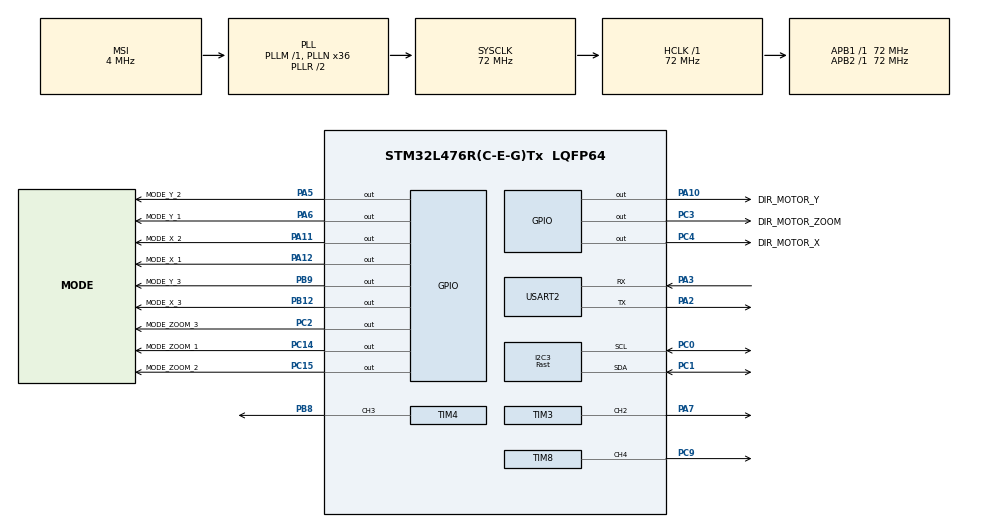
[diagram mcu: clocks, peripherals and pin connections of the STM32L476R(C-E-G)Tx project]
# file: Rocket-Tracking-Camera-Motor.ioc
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FREERTOS.Tasks01=defaultTask,24,128,StartDefaultTask,Default,NULL,Dynamic,NULL,NULL;motor_control,32,128,tsk_motor_control,As external,NULL,Dynamic,NULL,NULL;i2c,32,128,tsk_i2c,As external,NULL,Dynamic,NULL,NULL
FREERTOS.configUSE_NEWLIB_REENTRANT=1
I2C3.I2C_Speed_Mode=I2C_Fast
I2C3.OwnAddress=0x23
I2C3.Timing=0x00702681
Mcu.Family=STM32L4
Mcu.Name=STM32L476R(C-E-G)Tx
Mcu.Package=LQFP64
NVIC.I2C3_ER_IRQn=true\:5\:0\:false\:false\:true\:true\:true\:true\:true
NVIC.I2C3_EV_IRQn=true\:5\:0\:false\:false\:true\:true\:true\:true\:true
NVIC.PriorityGroup=NVIC_PRIORITYGROUP_4
NVIC.TIM1_UP_TIM16_IRQn=true\:15\:0\:false\:false\:true\:false\:false\:true\:true
NVIC.TimeBase=TIM1_UP_TIM16_IRQn
NVIC.TimeBaseIP=TIM1
PA10.GPIO_Label=DIR_MOTOR_Y
PA10.Signal=GPIO_Output
PA11.GPIO_Label=MODE_X_2
PA11.Signal=GPIO_Output
PA12.GPIO_Label=MODE_X_1
PA12.Signal=GPIO_Output
PA13\ (JTMS-SWDIO).Mode=Trace_Asynchronous_SW
PA13\ (JTMS-SWDIO).Signal=SYS_JTMS-SWDIO
PA14\ (JTCK-SWCLK).Mode=Trace_Asynchronous_SW
PA14\ (JTCK-SWCLK).Signal=SYS_JTCK-SWCLK
PA2.Mode=Asynchronous
PA2.Signal=USART2_TX
PA3.Mode=Asynchronous
PA3.Signal=USART2_RX
PA5.GPIO_Label=MODE_Y_2
PA5.Signal=GPIO_Output
PA6.GPIO_Label=MODE_Y_1
PA6.Signal=GPIO_Output
PA7.Signal=S_TIM3_CH2
PB12.GPIO_Label=MODE_X_3
PB12.Signal=GPIO_Output
PB13.Signal=I2C2_SCL
PB14.Signal=I2C2_SDA
PB3\ (JTDO-TRACESWO).Mode=Trace_Asynchronous_SW
PB3\ (JTDO-TRACESWO).Signal=SYS_JTDO-SWO
PB8.Signal=S_TIM4_CH3
PB9.GPIO_Label=MODE_Y_3
PB9.Signal=GPIO_Output
PC0.Mode=I2C
PC0.Signal=I2C3_SCL
PC1.Mode=I2C
PC1.Signal=I2C3_SDA
PC14-OSC32_IN\ (PC14).GPIO_Label=MODE_ZOOM_1
PC14-OSC32_IN\ (PC14).Signal=GPIO_Output
PC15-OSC32_OUT\ (PC15).GPIO_Label=MODE_ZOOM_2
PC15-OSC32_OUT\ (PC15).Signal=GPIO_Output
PC2.GPIO_Label=MODE_ZOOM_3
PC2.Signal=GPIO_Output
PC3.GPIO_Label=DIR_MOTOR_ZOOM
PC3.Signal=GPIO_Output
PC4.GPIO_Label=DIR_MOTOR_X
PC4.Signal=GPIO_Output
PC9.Signal=S_TIM8_CH4
PH0-OSC_IN\ (PH0).Mode=HSE-External-Oscillator
PH0-OSC_IN\ (PH0).Signal=RCC_OSC_IN
PH1-OSC_OUT\ (PH1).Mode=HSE-External-Oscillator
PH1-OSC_OUT\ (PH1).Signal=RCC_OSC_OUT
ProjectManager.HeapSize=0x200
ProjectManager.StackSize=0x400
ProjectManager.TargetToolchain=STM32CubeIDE
RCC.AHBFreq_Value=72000000
RCC.APB1Freq_Value=72000000
RCC.APB1TimFreq_Value=72000000
RCC.APB2Freq_Value=72000000
RCC.APB2TimFreq_Value=72000000
RCC.CortexFreq_Value=72000000
RCC.HCLKFreq_Value=72000000
RCC.HSE_VALUE=8000000
RCC.HSI_VALUE=16000000
RCC.LSE_VALUE=32768
RCC.MSI_VALUE=4000000
RCC.PLLN=36
RCC.SYSCLKFreq_VALUE=72000000
RCC.SYSCLKSource=RCC_SYSCLKSOURCE_PLLCLK
RCC.VCOOutputFreq_Value=144000000
SH.S_TIM3_CH2.0=TIM3_CH2,PWM Generation2 CH2
SH.S_TIM4_CH3.0=TIM4_CH3,PWM Generation3 CH3
SH.S_TIM8_CH4.0=TIM8_CH4,PWM Generation4 CH4
TIM3.AutoReloadPreload=TIM_AUTORELOAD_PRELOAD_ENABLE
TIM3.Channel-PWM\ Generation2\ CH2=TIM_CHANNEL_2
TIM4.AutoReloadPreload=TIM_AUTORELOAD_PRELOAD_ENABLE
TIM4.Channel-PWM\ Generation3\ CH3=TIM_CHANNEL_3
TIM8.AutoReloadPreload=TIM_AUTORELOAD_PRELOAD_ENABLE
TIM8.Channel-PWM\ Generation4\ CH4=TIM_CHANNEL_4
USART2.VirtualMode-Asynchronous=VM_ASYNC
VP_FREERTOS_VS_CMSIS_V2.Mode=CMSIS_V2
VP_SYS_VS_tim1.Mode=TIM1
VP_TIM3_VS_ClockSourceINT.Mode=Internal
VP_TIM4_VS_ClockSourceINT.Mode=Internal
VP_TIM8_VS_ClockSourceINT.Mode=Internal
board=custom

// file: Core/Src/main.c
/* USER CODE BEGIN Header */
/**
  ******************************************************************************
  * @file           : main.c
  * @brief          : Main program body
  ******************************************************************************
  * @attention
  *
  * Copyright (c) 2023 STMicroelectronics.
  * All rights reserved.
  *
  * This software is licensed under terms that can be found in the LICENSE file
  * in the root directory of this software component.
  * If no LICENSE file comes with this software, it is provided AS-IS.
  *
  ******************************************************************************
  */
/* USER CODE END Header */
#include "main.h"
#include "cmsis_os.h"

/* USER CODE BEGIN Includes */
#include <string.h>

/* USER CODE END Includes */

I2C_HandleTypeDef hi2c3;

TIM_HandleTypeDef htim3;
TIM_HandleTypeDef htim4;
TIM_HandleTypeDef htim8;

UART_HandleTypeDef huart2;

/* Definitions for defaultTask */
osThreadId_t defaultTaskHandle;
const osThreadAttr_t defaultTask_attributes = {
  .name = "defaultTask",
  .stack_size = 128 * 4,
  .priority = (osPriority_t) osPriorityNormal,
};
/* Definitions for motor_control */
osThreadId_t motor_controlHandle;
const osThreadAttr_t motor_control_attributes = {
  .name = "motor_control",
  .stack_size = 128 * 4,
  .priority = (osPriority_t) osPriorityAboveNormal,
};
/* Definitions for i2c */
osThreadId_t i2cHandle;
const osThreadAttr_t i2c_attributes = {
  .name = "i2c",
  .stack_size = 128 * 4,
  .priority = (osPriority_t) osPriorityAboveNormal,
};

void SystemClock_Config(void);
static void MX_GPIO_Init(void);
static void MX_TIM3_Init(void);
static void MX_TIM8_Init(void);
static void MX_TIM4_Init(void);
static void MX_USART2_UART_Init(void);
static void MX_I2C3_Init(void);
void StartDefaultTask(void *argument);
extern void tsk_motor_control(void *argument);
extern void tsk_i2c(void *argument);

/* USER CODE BEGIN 0 */

TIM_HandleTypeDef* get_htim3()  { return &htim3;}
TIM_HandleTypeDef* get_htim4()  { return &htim4;}
TIM_HandleTypeDef* get_htim8()  { return &htim8;}
I2C_HandleTypeDef* get_hi2cl()  { return &hi2c3; }
UART_HandleTypeDef* get_huart2(){ return &huart2; }

/* USER CODE END 0 */

int main(void)
{

  /* MCU Configuration--------------------------------------------------------*/

  /* Reset of all peripherals, Initializes the Flash interface and the Systick. */
  HAL_Init();

  /* Configure the system clock */
  SystemClock_Config();

  /* Initialize all configured peripherals */
  MX_GPIO_Init();
  MX_TIM3_Init();
  MX_TIM8_Init();
  MX_TIM4_Init();
  MX_USART2_UART_Init();
  MX_I2C3_Init();
  /* USER CODE BEGIN 2 */
  uint8_t debug_buf[4];
  strcpy((char*) debug_buf, "Reset\r\n");
  HAL_UART_Transmit(get_huart2(), debug_buf, strlen((char*)debug_buf), HAL_MAX_DELAY);
  /* USER CODE END 2 */

  /* Init scheduler */
  osKernelInitialize();

  /* Create the thread(s) */
  /* creation of defaultTask */
  defaultTaskHandle = osThreadNew(StartDefaultTask, NULL, &defaultTask_attributes);

  /* creation of motor_control */
  motor_controlHandle = osThreadNew(tsk_motor_control, NULL, &motor_control_attributes);

  /* creation of i2c */
  i2cHandle = osThreadNew(tsk_i2c, NULL, &i2c_attributes);

  /* Start scheduler */
  osKernelStart();
  /* We should never get here as control is now taken by the scheduler */
  /* Infinite loop */
  while (1)
  {

  }
}

void SystemClock_Config(void)
{
  RCC_OscInitTypeDef RCC_OscInitStruct = {0};
  RCC_ClkInitTypeDef RCC_ClkInitStruct = {0};

  /** Configure the main internal regulator output voltage
  */
  if (HAL_PWREx_ControlVoltageScaling(PWR_REGULATOR_VOLTAGE_SCALE1) != HAL_OK)
  {
    Error_Handler();
  }

  /** Initializes the RCC Oscillators according to the specified parameters
  * in the RCC_OscInitTypeDef structure.
  */
  RCC_OscInitStruct.OscillatorType = RCC_OSCILLATORTYPE_MSI;
  RCC_OscInitStruct.MSIState = RCC_MSI_ON;
  RCC_OscInitStruct.MSICalibrationValue = 0;
  RCC_OscInitStruct.MSIClockRange = RCC_MSIRANGE_6;
  RCC_OscInitStruct.PLL.PLLState = RCC_PLL_ON;
  RCC_OscInitStruct.PLL.PLLSource = RCC_PLLSOURCE_MSI;
  RCC_OscInitStruct.PLL.PLLM = 1;
  RCC_OscInitStruct.PLL.PLLN = 36;
  RCC_OscInitStruct.PLL.PLLP = RCC_PLLP_DIV7;
  RCC_OscInitStruct.PLL.PLLQ = RCC_PLLQ_DIV2;
  RCC_OscInitStruct.PLL.PLLR = RCC_PLLR_DIV2;
  if (HAL_RCC_OscConfig(&RCC_OscInitStruct) != HAL_OK)
  {
    Error_Handler();
  }

  /** Initializes the CPU, AHB and APB buses clocks
  */
  RCC_ClkInitStruct.ClockType = RCC_CLOCKTYPE_HCLK|RCC_CLOCKTYPE_SYSCLK
                              |RCC_CLOCKTYPE_PCLK1|RCC_CLOCKTYPE_PCLK2;
  RCC_ClkInitStruct.SYSCLKSource = RCC_SYSCLKSOURCE_PLLCLK;
  RCC_ClkInitStruct.AHBCLKDivider = RCC_SYSCLK_DIV1;
  RCC_ClkInitStruct.APB1CLKDivider = RCC_HCLK_DIV1;
  RCC_ClkInitStruct.APB2CLKDivider = RCC_HCLK_DIV1;

  if (HAL_RCC_ClockConfig(&RCC_ClkInitStruct, FLASH_LATENCY_4) != HAL_OK)
  {
    Error_Handler();
  }
}

static void MX_I2C3_Init(void)
{

  hi2c3.Instance = I2C3;
  hi2c3.Init.Timing = 0x00702681;
  hi2c3.Init.OwnAddress1 = 70;
  hi2c3.Init.AddressingMode = I2C_ADDRESSINGMODE_7BIT;
  hi2c3.Init.DualAddressMode = I2C_DUALADDRESS_DISABLE;
  hi2c3.Init.OwnAddress2 = 0;
  hi2c3.Init.OwnAddress2Masks = I2C_OA2_NOMASK;
  hi2c3.Init.GeneralCallMode = I2C_GENERALCALL_DISABLE;
  hi2c3.Init.NoStretchMode = I2C_NOSTRETCH_DISABLE;
  if (HAL_I2C_Init(&hi2c3) != HAL_OK)
  {
    Error_Handler();
  }

  /** Configure Analogue filter
  */
  if (HAL_I2CEx_ConfigAnalogFilter(&hi2c3, I2C_ANALOGFILTER_ENABLE) != HAL_OK)
  {
    Error_Handler();
  }

  /** Configure Digital filter
  */
  if (HAL_I2CEx_ConfigDigitalFilter(&hi2c3, 0) != HAL_OK)
  {
    Error_Handler();
  }

}

static void MX_TIM3_Init(void)
{

  TIM_ClockConfigTypeDef sClockSourceConfig = {0};
  TIM_MasterConfigTypeDef sMasterConfig = {0};
  TIM_OC_InitTypeDef sConfigOC = {0};

  htim3.Instance = TIM3;
  htim3.Init.Prescaler = 0;
  htim3.Init.CounterMode = TIM_COUNTERMODE_UP;
  htim3.Init.Period = 65535;
  htim3.Init.ClockDivision = TIM_CLOCKDIVISION_DIV1;
  htim3.Init.AutoReloadPreload = TIM_AUTORELOAD_PRELOAD_ENABLE;
  if (HAL_TIM_Base_Init(&htim3) != HAL_OK)
  {
    Error_Handler();
  }
  sClockSourceConfig.ClockSource = TIM_CLOCKSOURCE_INTERNAL;
  if (HAL_TIM_ConfigClockSource(&htim3, &sClockSourceConfig) != HAL_OK)
  {
    Error_Handler();
  }
  if (HAL_TIM_PWM_Init(&htim3) != HAL_OK)
  {
    Error_Handler();
  }
  sMasterConfig.MasterOutputTrigger = TIM_TRGO_RESET;
  sMasterConfig.MasterSlaveMode = TIM_MASTERSLAVEMODE_DISABLE;
  if (HAL_TIMEx_MasterConfigSynchronization(&htim3, &sMasterConfig) != HAL_OK)
  {
    Error_Handler();
  }
  sConfigOC.OCMode = TIM_OCMODE_PWM1;
  sConfigOC.Pulse = 0;
  sConfigOC.OCPolarity = TIM_OCPOLARITY_HIGH;
  sConfigOC.OCFastMode = TIM_OCFAST_DISABLE;
  if (HAL_TIM_PWM_ConfigChannel(&htim3, &sConfigOC, TIM_CHANNEL_2) != HAL_OK)
  {
    Error_Handler();
  }
  HAL_TIM_MspPostInit(&htim3);

}

static void MX_TIM4_Init(void)
{

  TIM_ClockConfigTypeDef sClockSourceConfig = {0};
  TIM_MasterConfigTypeDef sMasterConfig = {0};
  TIM_OC_InitTypeDef sConfigOC = {0};

  htim4.Instance = TIM4;
  htim4.Init.Prescaler = 0;
  htim4.Init.CounterMode = TIM_COUNTERMODE_UP;
  htim4.Init.Period = 65535;
  htim4.Init.ClockDivision = TIM_CLOCKDIVISION_DIV1;
  htim4.Init.AutoReloadPreload = TIM_AUTORELOAD_PRELOAD_ENABLE;
  if (HAL_TIM_Base_Init(&htim4) != HAL_OK)
  {
    Error_Handler();
  }
  sClockSourceConfig.ClockSource = TIM_CLOCKSOURCE_INTERNAL;
  if (HAL_TIM_ConfigClockSource(&htim4, &sClockSourceConfig) != HAL_OK)
  {
    Error_Handler();
  }
  if (HAL_TIM_PWM_Init(&htim4) != HAL_OK)
  {
    Error_Handler();
  }
  sMasterConfig.MasterOutputTrigger = TIM_TRGO_RESET;
  sMasterConfig.MasterSlaveMode = TIM_MASTERSLAVEMODE_DISABLE;
  if (HAL_TIMEx_MasterConfigSynchronization(&htim4, &sMasterConfig) != HAL_OK)
  {
    Error_Handler();
  }
  sConfigOC.OCMode = TIM_OCMODE_PWM1;
  sConfigOC.Pulse = 0;
  sConfigOC.OCPolarity = TIM_OCPOLARITY_HIGH;
  sConfigOC.OCFastMode = TIM_OCFAST_DISABLE;
  if (HAL_TIM_PWM_ConfigChannel(&htim4, &sConfigOC, TIM_CHANNEL_3) != HAL_OK)
  {
    Error_Handler();
  }
  HAL_TIM_MspPostInit(&htim4);

}

static void MX_TIM8_Init(void)
{

  TIM_ClockConfigTypeDef sClockSourceConfig = {0};
  TIM_MasterConfigTypeDef sMasterConfig = {0};
  TIM_OC_InitTypeDef sConfigOC = {0};
  TIM_BreakDeadTimeConfigTypeDef sBreakDeadTimeConfig = {0};

  htim8.Instance = TIM8;
  htim8.Init.Prescaler = 0;
  htim8.Init.CounterMode = TIM_COUNTERMODE_UP;
  htim8.Init.Period = 65535;
  htim8.Init.ClockDivision = TIM_CLOCKDIVISION_DIV1;
  htim8.Init.RepetitionCounter = 0;
  htim8.Init.AutoReloadPreload = TIM_AUTORELOAD_PRELOAD_ENABLE;
  if (HAL_TIM_Base_Init(&htim8) != HAL_OK)
  {
    Error_Handler();
  }
  sClockSourceConfig.ClockSource = TIM_CLOCKSOURCE_INTERNAL;
  if (HAL_TIM_ConfigClockSource(&htim8, &sClockSourceConfig) != HAL_OK)
  {
    Error_Handler();
  }
  if (HAL_TIM_PWM_Init(&htim8) != HAL_OK)
  {
    Error_Handler();
  }
  sMasterConfig.MasterOutputTrigger = TIM_TRGO_RESET;
  sMasterConfig.MasterOutputTrigger2 = TIM_TRGO2_RESET;
  sMasterConfig.MasterSlaveMode = TIM_MASTERSLAVEMODE_DISABLE;
  if (HAL_TIMEx_MasterConfigSynchronization(&htim8, &sMasterConfig) != HAL_OK)
  {
    Error_Handler();
  }
  sConfigOC.OCMode = TIM_OCMODE_PWM1;
  sConfigOC.Pulse = 0;
  sConfigOC.OCPolarity = TIM_OCPOLARITY_HIGH;
  sConfigOC.OCFastMode = TIM_OCFAST_DISABLE;
  sConfigOC.OCIdleState = TIM_OCIDLESTATE_RESET;
  sConfigOC.OCNIdleState = TIM_OCNIDLESTATE_RESET;
  if (HAL_TIM_PWM_ConfigChannel(&htim8, &sConfigOC, TIM_CHANNEL_4) != HAL_OK)
  {
    Error_Handler();
  }
  sBreakDeadTimeConfig.OffStateRunMode = TIM_OSSR_DISABLE;
  sBreakDeadTimeConfig.OffStateIDLEMode = TIM_OSSI_DISABLE;
  sBreakDeadTimeConfig.LockLevel = TIM_LOCKLEVEL_OFF;
  sBreakDeadTimeConfig.DeadTime = 0;
  sBreakDeadTimeConfig.BreakState = TIM_BREAK_DISABLE;
  sBreakDeadTimeConfig.BreakPolarity = TIM_BREAKPOLARITY_HIGH;
  sBreakDeadTimeConfig.BreakFilter = 0;
  sBreakDeadTimeConfig.Break2State = TIM_BREAK2_DISABLE;
  sBreakDeadTimeConfig.Break2Polarity = TIM_BREAK2POLARITY_HIGH;
  sBreakDeadTimeConfig.Break2Filter = 0;
  sBreakDeadTimeConfig.AutomaticOutput = TIM_AUTOMATICOUTPUT_DISABLE;
  if (HAL_TIMEx_ConfigBreakDeadTime(&htim8, &sBreakDeadTimeConfig) != HAL_OK)
  {
    Error_Handler();
  }
  HAL_TIM_MspPostInit(&htim8);

}

static void MX_USART2_UART_Init(void)
{

  huart2.Instance = USART2;
  huart2.Init.BaudRate = 115200;
  huart2.Init.WordLength = UART_WORDLENGTH_8B;
  huart2.Init.StopBits = UART_STOPBITS_1;
  huart2.Init.Parity = UART_PARITY_NONE;
  huart2.Init.Mode = UART_MODE_TX_RX;
  huart2.Init.HwFlowCtl = UART_HWCONTROL_NONE;
  huart2.Init.OverSampling = UART_OVERSAMPLING_16;
  huart2.Init.OneBitSampling = UART_ONE_BIT_SAMPLE_DISABLE;
  huart2.AdvancedInit.AdvFeatureInit = UART_ADVFEATURE_NO_INIT;
  if (HAL_UART_Init(&huart2) != HAL_OK)
  {
    Error_Handler();
  }

}

static void MX_GPIO_Init(void)
{
  GPIO_InitTypeDef GPIO_InitStruct = {0};

  /* GPIO Ports Clock Enable */
  __HAL_RCC_GPIOC_CLK_ENABLE();
  __HAL_RCC_GPIOH_CLK_ENABLE();
  __HAL_RCC_GPIOA_CLK_ENABLE();
  __HAL_RCC_GPIOB_CLK_ENABLE();

  /*Configure GPIO pin Output Level */
  HAL_GPIO_WritePin(GPIOC, MODE_ZOOM_1_Pin|MODE_ZOOM_2_Pin|MODE_ZOOM_3_Pin|DIR_MOTOR_ZOOM_Pin
                          |DIR_MOTOR_X_Pin, GPIO_PIN_RESET);

  /*Configure GPIO pin Output Level */
  HAL_GPIO_WritePin(GPIOA, MODE_Y_2_Pin|MODE_Y_1_Pin|DIR_MOTOR_Y_Pin|MODE_X_2_Pin
                          |MODE_X_1_Pin, GPIO_PIN_RESET);

  /*Configure GPIO pin Output Level */
  HAL_GPIO_WritePin(GPIOB, MODE_X_3_Pin|MODE_Y_3_Pin, GPIO_PIN_RESET);

  /*Configure GPIO pins : MODE_ZOOM_1_Pin MODE_ZOOM_2_Pin MODE_ZOOM_3_Pin DIR_MOTOR_ZOOM_Pin
                           DIR_MOTOR_X_Pin */
  GPIO_InitStruct.Pin = MODE_ZOOM_1_Pin|MODE_ZOOM_2_Pin|MODE_ZOOM_3_Pin|DIR_MOTOR_ZOOM_Pin
                          |DIR_MOTOR_X_Pin;
  GPIO_InitStruct.Mode = GPIO_MODE_OUTPUT_PP;
  GPIO_InitStruct.Pull = GPIO_NOPULL;
  GPIO_InitStruct.Speed = GPIO_SPEED_FREQ_LOW;
  HAL_GPIO_Init(GPIOC, &GPIO_InitStruct);

  /*Configure GPIO pins : MODE_Y_2_Pin MODE_Y_1_Pin DIR_MOTOR_Y_Pin MODE_X_2_Pin
                           MODE_X_1_Pin */
  GPIO_InitStruct.Pin = MODE_Y_2_Pin|MODE_Y_1_Pin|DIR_MOTOR_Y_Pin|MODE_X_2_Pin
                          |MODE_X_1_Pin;
  GPIO_InitStruct.Mode = GPIO_MODE_OUTPUT_PP;
  GPIO_InitStruct.Pull = GPIO_NOPULL;
  GPIO_InitStruct.Speed = GPIO_SPEED_FREQ_LOW;
  HAL_GPIO_Init(GPIOA, &GPIO_InitStruct);

  /*Configure GPIO pins : MODE_X_3_Pin MODE_Y_3_Pin */
  GPIO_InitStruct.Pin = MODE_X_3_Pin|MODE_Y_3_Pin;
  GPIO_InitStruct.Mode = GPIO_MODE_OUTPUT_PP;
  GPIO_InitStruct.Pull = GPIO_NOPULL;
  GPIO_InitStruct.Speed = GPIO_SPEED_FREQ_LOW;
  HAL_GPIO_Init(GPIOB, &GPIO_InitStruct);

  /*Configure GPIO pins : PB13 PB14 */
  GPIO_InitStruct.Pin = GPIO_PIN_13|GPIO_PIN_14;
  GPIO_InitStruct.Mode = GPIO_MODE_AF_OD;
  GPIO_InitStruct.Pull = GPIO_NOPULL;
  GPIO_InitStruct.Speed = GPIO_SPEED_FREQ_VERY_HIGH;
  GPIO_InitStruct.Alternate = GPIO_AF4_I2C2;
  HAL_GPIO_Init(GPIOB, &GPIO_InitStruct);

}

void StartDefaultTask(void *argument)
{
  /* USER CODE BEGIN 5 */
  /* Infinite loop */
	for(;;) {
		osDelay(1000);
	}
  /* USER CODE END 5 */
}

void HAL_TIM_PeriodElapsedCallback(TIM_HandleTypeDef *htim)
{
  if (htim->Instance == TIM1) {
    HAL_IncTick();
  }
}

void Error_Handler(void)
{
  __disable_irq();
  while (1)
  {
  }
}
